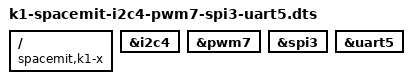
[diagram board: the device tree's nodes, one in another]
/dts-v1/;
/plugin/;

// Enable 26pin I2C4, PWM7, SPI3 and UART5
// https://forum.banana-pi.org/t/bananapif3-gpio-wiringpi-gpiod-python3-periphery-adafruit-blinka-and-luma-examples/18948

/ {
	compatible = "spacemit,k1-x";

	fragment@0 {
		target = <&i2c4>;
		__overlay__ {
			status = "okay";
		};
	};

	fragment@1 {
		target = <&pwm7>;
		__overlay__ {
			status = "okay";
		};
	};

	fragment@2 {
		target = <&spi3>;
		__overlay__ {
			status = "okay";
		};
	};

	fragment@3 {
		target = <&uart5>;
		__overlay__ {
			status = "okay";
		};
	};
};
